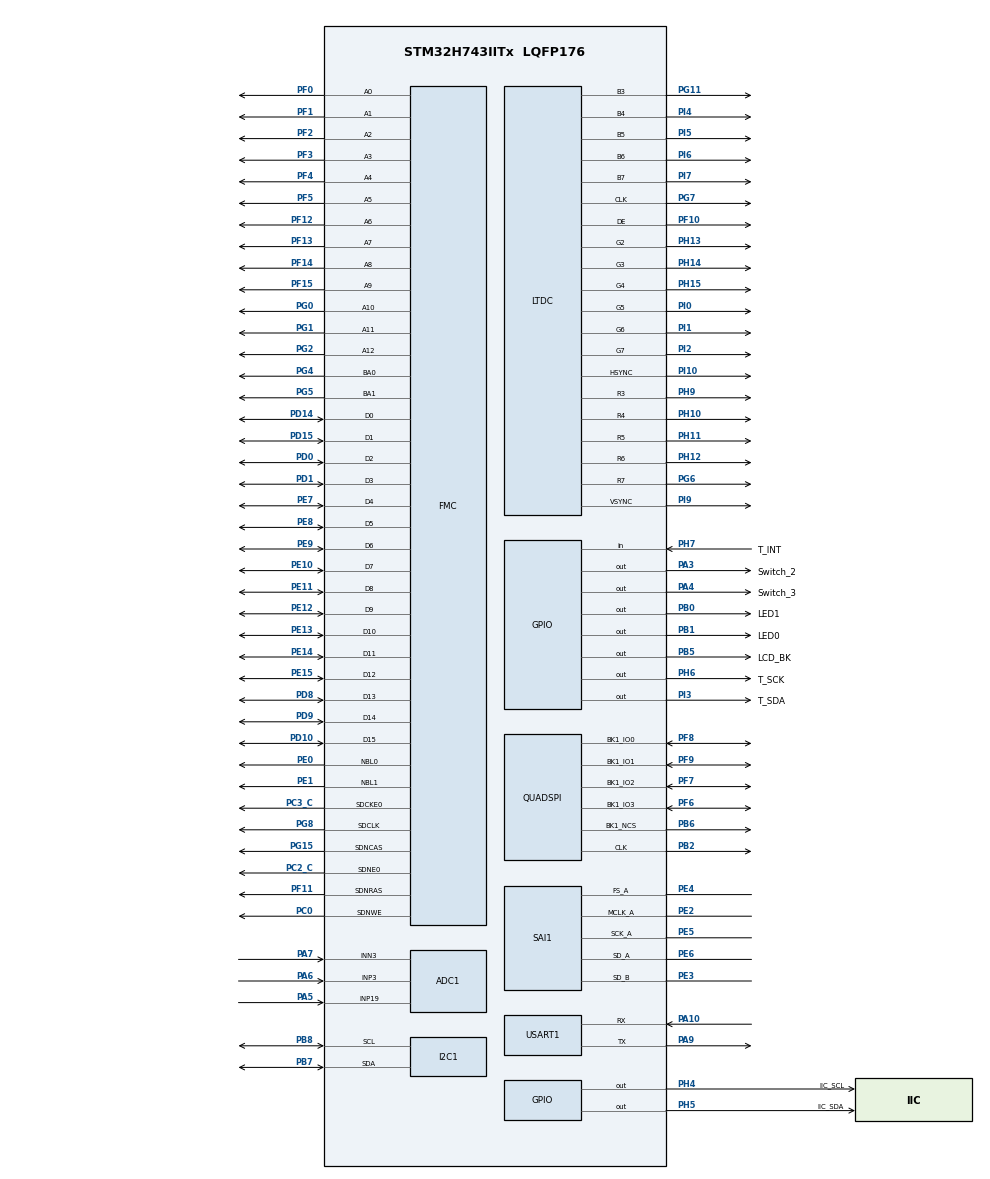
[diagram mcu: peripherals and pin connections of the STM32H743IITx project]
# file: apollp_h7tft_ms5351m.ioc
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ADC1.Channel-0\#ChannelRegularConversion=ADC_CHANNEL_19
ADC1.ClockPrescaler=ADC_CLOCK_ASYNC_DIV4
ADC1.ClockPrescalerADC3=ADC_CLOCK_ASYNC_DIV4
ADC1.ConversionDataManagement=ADC_CONVERSIONDATA_DMA_ONESHOT
ADC1.EOCSelection=ADC_EOC_SEQ_CONV
ADC1.EnableInjectedConversion=ENABLE
ADC1.ExternalTrigConv=ADC_SOFTWARE_START
ADC1.ExternalTrigInjecConv=ADC_EXTERNALTRIGINJEC_T3_TRGO
ADC1.InjNumberOfConversion=1
ADC1.InjectedChannel-1\#ChannelInjectedConversion=ADC_CHANNEL_3
ADC1.InjectedOffsetNumber-1\#ChannelInjectedConversion=ADC_OFFSET_NONE
ADC1.InjectedOffsetSaturation-1\#ChannelInjectedConversion=DISABLE
ADC1.InjectedOffsetSignedSaturation-1\#ChannelInjectedConversion=DISABLE
ADC1.InjectedRank-1\#ChannelInjectedConversion=1
ADC1.InjectedSamplingTime-1\#ChannelInjectedConversion=ADC_SAMPLETIME_64CYCLES_5
ADC1.InjectedSingleDiff-1\#ChannelInjectedConversion=ADC_DIFFERENTIAL_ENDED
ADC1.NbrOfConversionFlag=1
ADC1.OffsetNumber-0\#ChannelRegularConversion=ADC_OFFSET_NONE
ADC1.OffsetSignedSaturation-0\#ChannelRegularConversion=DISABLE
ADC1.Overrun=ADC_OVR_DATA_OVERWRITTEN
ADC1.Rank-0\#ChannelRegularConversion=1
ADC1.SamplingTime-0\#ChannelRegularConversion=ADC_SAMPLETIME_64CYCLES_5
ADC1.master=1
ADC3.Channel-0\#ChannelRegularConversion=ADC_CHANNEL_TEMPSENSOR
ADC3.ClockPrescaler=ADC_CLOCK_ASYNC_DIV4
ADC3.ClockPrescalerADC3=ADC_CLOCK_ASYNC_DIV4
ADC3.NbrOfConversionFlag=1
ADC3.OffsetNumber-0\#ChannelRegularConversion=ADC_OFFSET_NONE
ADC3.OffsetSignedSaturation-0\#ChannelRegularConversion=DISABLE
ADC3.Overrun=ADC_OVR_DATA_OVERWRITTEN
ADC3.Rank-0\#ChannelRegularConversion=1
ADC3.SamplingTime-0\#ChannelRegularConversion=ADC_SAMPLETIME_810CYCLES_5
CORTEX_M7.AccessPermission-Cortex_Memory_Protection_Unit_Region1_Settings=MPU_REGION_FULL_ACCESS
CORTEX_M7.AccessPermission-Cortex_Memory_Protection_Unit_Region2_Settings=MPU_REGION_FULL_ACCESS
CORTEX_M7.AccessPermission-Cortex_Memory_Protection_Unit_Region3_Settings=MPU_REGION_FULL_ACCESS
CORTEX_M7.AccessPermission-Cortex_Memory_Protection_Unit_Region4_Settings=MPU_REGION_FULL_ACCESS
CORTEX_M7.AccessPermission-Cortex_Memory_Protection_Unit_Region5_Settings=MPU_REGION_FULL_ACCESS
CORTEX_M7.AccessPermission-Cortex_Memory_Protection_Unit_Region6_Settings=MPU_REGION_FULL_ACCESS
CORTEX_M7.BaseAddress-Cortex_Memory_Protection_Unit_Region1_Settings=0x24000000
CORTEX_M7.BaseAddress-Cortex_Memory_Protection_Unit_Region2_Settings=0xC0000000
CORTEX_M7.BaseAddress-Cortex_Memory_Protection_Unit_Region3_Settings=0x20000000
CORTEX_M7.BaseAddress-Cortex_Memory_Protection_Unit_Region4_Settings=0x30000000
CORTEX_M7.BaseAddress-Cortex_Memory_Protection_Unit_Region5_Settings=0x38000000
CORTEX_M7.BaseAddress-Cortex_Memory_Protection_Unit_Region6_Settings=0x60000000
CORTEX_M7.CPU_DCache=Enabled
CORTEX_M7.CPU_ICache=Enabled
CORTEX_M7.Enable-Cortex_Memory_Protection_Unit_Region0_Settings=__NULL
CORTEX_M7.Enable-Cortex_Memory_Protection_Unit_Region1_Settings=MPU_REGION_ENABLE
CORTEX_M7.Enable-Cortex_Memory_Protection_Unit_Region2_Settings=MPU_REGION_ENABLE
CORTEX_M7.Enable-Cortex_Memory_Protection_Unit_Region3_Settings=MPU_REGION_ENABLE
CORTEX_M7.Enable-Cortex_Memory_Protection_Unit_Region4_Settings=MPU_REGION_ENABLE
CORTEX_M7.Enable-Cortex_Memory_Protection_Unit_Region5_Settings=MPU_REGION_ENABLE
CORTEX_M7.Enable-Cortex_Memory_Protection_Unit_Region6_Settings=MPU_REGION_ENABLE
CORTEX_M7.IsBufferable-Cortex_Memory_Protection_Unit_Region1_Settings=MPU_ACCESS_BUFFERABLE
CORTEX_M7.IsBufferable-Cortex_Memory_Protection_Unit_Region2_Settings=MPU_ACCESS_BUFFERABLE
CORTEX_M7.IsBufferable-Cortex_Memory_Protection_Unit_Region3_Settings=MPU_ACCESS_BUFFERABLE
CORTEX_M7.IsBufferable-Cortex_Memory_Protection_Unit_Region4_Settings=MPU_ACCESS_BUFFERABLE
CORTEX_M7.IsBufferable-Cortex_Memory_Protection_Unit_Region5_Settings=MPU_ACCESS_BUFFERABLE
CORTEX_M7.IsCacheable-Cortex_Memory_Protection_Unit_Region1_Settings=MPU_ACCESS_CACHEABLE
CORTEX_M7.IsCacheable-Cortex_Memory_Protection_Unit_Region2_Settings=MPU_ACCESS_CACHEABLE
CORTEX_M7.IsCacheable-Cortex_Memory_Protection_Unit_Region3_Settings=MPU_ACCESS_CACHEABLE
CORTEX_M7.IsCacheable-Cortex_Memory_Protection_Unit_Region4_Settings=MPU_ACCESS_CACHEABLE
CORTEX_M7.IsShareable-Cortex_Memory_Protection_Unit_Region1_Settings=MPU_ACCESS_NOT_SHAREABLE
CORTEX_M7.MPU_Control=MPU_PRIVILEGED_DEFAULT
CORTEX_M7.Size-Cortex_Memory_Protection_Unit_Region1_Settings=MPU_REGION_SIZE_512KB
CORTEX_M7.Size-Cortex_Memory_Protection_Unit_Region2_Settings=MPU_REGION_SIZE_32MB
CORTEX_M7.Size-Cortex_Memory_Protection_Unit_Region3_Settings=MPU_REGION_SIZE_128KB
CORTEX_M7.Size-Cortex_Memory_Protection_Unit_Region4_Settings=MPU_REGION_SIZE_512KB
CORTEX_M7.Size-Cortex_Memory_Protection_Unit_Region5_Settings=MPU_REGION_SIZE_64KB
CORTEX_M7.Size-Cortex_Memory_Protection_Unit_Region6_Settings=MPU_REGION_SIZE_64MB
CORTEX_M7.default_mode_Activation=0
DMA2D.ColorMode=DMA2D_OUTPUT_RGB565
Dma.ADC1.0.Direction=DMA_PERIPH_TO_MEMORY
Dma.ADC1.0.EventEnable=DISABLE
Dma.ADC1.0.FIFOMode=DMA_FIFOMODE_DISABLE
Dma.ADC1.0.Instance=DMA1_Stream0
Dma.ADC1.0.MemDataAlignment=DMA_MDATAALIGN_HALFWORD
Dma.ADC1.0.MemInc=DMA_MINC_ENABLE
Dma.ADC1.0.Mode=DMA_CIRCULAR
Dma.ADC1.0.PeriphDataAlignment=DMA_PDATAALIGN_HALFWORD
Dma.ADC1.0.PeriphInc=DMA_PINC_DISABLE
Dma.ADC1.0.Polarity=HAL_DMAMUX_REQ_GEN_RISING
Dma.ADC1.0.Priority=DMA_PRIORITY_LOW
Dma.ADC1.0.RequestNumber=1
Dma.ADC1.0.SignalID=NONE
Dma.ADC1.0.SyncEnable=DISABLE
Dma.ADC1.0.SyncPolarity=HAL_DMAMUX_SYNC_NO_EVENT
Dma.ADC1.0.SyncRequestNumber=1
Dma.ADC1.0.SyncSignalID=NONE
Dma.MEMTOMEM.1.Direction=DMA_MEMORY_TO_MEMORY
Dma.MEMTOMEM.1.EventEnable=DISABLE
Dma.MEMTOMEM.1.FIFOMode=DMA_FIFOMODE_ENABLE
Dma.MEMTOMEM.1.FIFOThreshold=DMA_FIFO_THRESHOLD_1QUARTERFULL
Dma.MEMTOMEM.1.Instance=DMA2_Stream0
Dma.MEMTOMEM.1.MemBurst=DMA_MBURST_SINGLE
Dma.MEMTOMEM.1.MemDataAlignment=DMA_MDATAALIGN_HALFWORD
Dma.MEMTOMEM.1.MemInc=DMA_MINC_ENABLE
Dma.MEMTOMEM.1.Mode=DMA_NORMAL
Dma.MEMTOMEM.1.PeriphBurst=DMA_PBURST_SINGLE
Dma.MEMTOMEM.1.PeriphDataAlignment=DMA_PDATAALIGN_HALFWORD
Dma.MEMTOMEM.1.PeriphInc=DMA_PINC_ENABLE
Dma.MEMTOMEM.1.Polarity=HAL_DMAMUX_REQ_GEN_RISING
Dma.MEMTOMEM.1.Priority=DMA_PRIORITY_HIGH
Dma.MEMTOMEM.1.RequestNumber=1
Dma.MEMTOMEM.1.SignalID=NONE
Dma.MEMTOMEM.1.SyncEnable=DISABLE
Dma.MEMTOMEM.1.SyncPolarity=HAL_DMAMUX_SYNC_NO_EVENT
Dma.MEMTOMEM.1.SyncRequestNumber=1
Dma.MEMTOMEM.1.SyncSignalID=NONE
Dma.Request0=ADC1
Dma.Request1=MEMTOMEM
Dma.Request2=SAI1_A
Dma.Request3=SAI1_B
Dma.SAI1_A.2.Direction=DMA_MEMORY_TO_PERIPH
Dma.SAI1_A.2.EventEnable=DISABLE
Dma.SAI1_A.2.FIFOMode=DMA_FIFOMODE_DISABLE
Dma.SAI1_A.2.Instance=DMA1_Stream5
Dma.SAI1_A.2.MemDataAlignment=DMA_MDATAALIGN_WORD
Dma.SAI1_A.2.MemInc=DMA_MINC_ENABLE
Dma.SAI1_A.2.Mode=DMA_CIRCULAR
Dma.SAI1_A.2.PeriphDataAlignment=DMA_PDATAALIGN_WORD
Dma.SAI1_A.2.PeriphInc=DMA_PINC_DISABLE
Dma.SAI1_A.2.Polarity=HAL_DMAMUX_REQ_GEN_RISING
Dma.SAI1_A.2.Priority=DMA_PRIORITY_LOW
Dma.SAI1_A.2.RequestNumber=1
Dma.SAI1_A.2.SignalID=NONE
Dma.SAI1_A.2.SyncEnable=DISABLE
Dma.SAI1_A.2.SyncPolarity=HAL_DMAMUX_SYNC_NO_EVENT
Dma.SAI1_A.2.SyncRequestNumber=1
Dma.SAI1_A.2.SyncSignalID=NONE
Dma.SAI1_B.3.Direction=DMA_PERIPH_TO_MEMORY
Dma.SAI1_B.3.EventEnable=DISABLE
Dma.SAI1_B.3.FIFOMode=DMA_FIFOMODE_DISABLE
Dma.SAI1_B.3.Instance=DMA1_Stream3
Dma.SAI1_B.3.MemDataAlignment=DMA_MDATAALIGN_WORD
Dma.SAI1_B.3.MemInc=DMA_MINC_ENABLE
Dma.SAI1_B.3.Mode=DMA_NORMAL
Dma.SAI1_B.3.PeriphDataAlignment=DMA_PDATAALIGN_WORD
Dma.SAI1_B.3.PeriphInc=DMA_PINC_DISABLE
Dma.SAI1_B.3.Polarity=HAL_DMAMUX_REQ_GEN_RISING
Dma.SAI1_B.3.Priority=DMA_PRIORITY_HIGH
Dma.SAI1_B.3.RequestNumber=1
Dma.SAI1_B.3.SignalID=NONE
Dma.SAI1_B.3.SyncEnable=DISABLE
Dma.SAI1_B.3.SyncPolarity=HAL_DMAMUX_SYNC_NO_EVENT
Dma.SAI1_B.3.SyncRequestNumber=1
Dma.SAI1_B.3.SyncSignalID=NONE
FMC.CASLatency1=FMC_SDRAM_CAS_LATENCY_3
FMC.ColumnBitsNumber1=FMC_SDRAM_COLUMN_BITS_NUM_9
FMC.ExitSelfRefreshDelay1=7
FMC.LoadToActiveDelay1=2
FMC.RCDDelay1=2
FMC.RPDelay1=2
FMC.RPDelay2=2
FMC.ReadBurst1=FMC_SDRAM_RBURST_ENABLE
FMC.ReadBurst2=FMC_SDRAM_RBURST_ENABLE
FMC.ReadPipeDelay1=FMC_SDRAM_RPIPE_DELAY_1
FMC.ReadPipeDelay2=FMC_SDRAM_RPIPE_DELAY_1
FMC.RowCycleDelay1=7
FMC.RowCycleDelay2=7
FMC.SDClockPeriod1=FMC_SDRAM_CLOCK_PERIOD_2
FMC.SDClockPeriod2=FMC_SDRAM_CLOCK_PERIOD_2
FMC.SelfRefreshTime1=4
FMC.WriteRecoveryTime1=3
I2C1.Timing=0x307075B1
LTDC.ActiveH=PIXELS_H
LTDC.ActiveW=PIXELS_W
LTDC.Alpha_L0=255
LTDC.Alpha_L1=255
LTDC.FBStartAdress_L0=0xC0000000
LTDC.FBStartAdress_L1=0xC0200000
LTDC.Green_L0=0
LTDC.HBP=140
LTDC.HFP=160
LTDC.HSync=20
LTDC.ImageHeight_L0=600
LTDC.ImageHeight_L1=600
LTDC.ImageWidth_L0=1024
LTDC.Layers=0
LTDC.PixelFormat_L0=LTDC_PIXEL_FORMAT_RGB565
LTDC.Red_L1=0
LTDC.VBP=20
LTDC.VFP=12
LTDC.VSync=3
LTDC.WindowX1_L0=PIXELS_W
LTDC.WindowX1_L1=PIXELS_W
LTDC.WindowY1_L0=PIXELS_H
LTDC.WindowY1_L1=PIXELS_H
Mcu.Family=STM32H7
Mcu.Name=STM32H743IITx
Mcu.Package=LQFP176
Mcu.UserConstants=PIXELS_DIR,1;PIXELS_H,600;PIXELS_W,1024;LTDC_BUFF_ADDR1,SDRAM_BANK_ADDR + SDRAM_LCD_SIZE;LTDC_BUFF_ADDR,SDRAM_BANK_ADDR
NVIC.ADC_IRQn=true\:0\:0\:false\:false\:true\:true\:true\:true
NVIC.DMA1_Stream0_IRQn=true\:2\:0\:true\:false\:true\:false\:true\:true
NVIC.DMA2D_IRQn=true\:0\:0\:false\:false\:true\:true\:true\:true
NVIC.PriorityGroup=NVIC_PRIORITYGROUP_4
NVIC.USART1_IRQn=true\:3\:0\:true\:false\:true\:true\:true\:true
PA10.Mode=Asynchronous
PA10.Signal=USART1_RX
PA13\ (JTMS/SWDIO).Mode=Serial_Wire
PA13\ (JTMS/SWDIO).Signal=DEBUG_JTMS-SWDIO
PA14\ (JTCK/SWCLK).Mode=Serial_Wire
PA14\ (JTCK/SWCLK).Signal=DEBUG_JTCK-SWCLK
PA3.GPIO_Label=Switch_2
PA3.GPIO_PuPd=GPIO_PULLUP
PA3.Signal=GPIO_Output
PA4.GPIO_Label=Switch_3
PA4.GPIO_PuPd=GPIO_PULLUP
PA4.Signal=GPIO_Output
PA5.Signal=ADCx_INP19
PA6.Signal=ADCx_INP3
PA7.Signal=ADCx_INN3
PA9.Mode=Asynchronous
PA9.Signal=USART1_TX
PB0.GPIO_Label=LED1
PB0.PinState=GPIO_PIN_SET
PB0.Signal=GPIO_Output
PB1.GPIO_Label=LED0
PB1.PinState=GPIO_PIN_SET
PB1.Signal=GPIO_Output
PB2.Mode=Single Bank 1
PB2.Signal=QUADSPI_CLK
PB5.GPIO_Label=LCD_BK
PB5.GPIO_PuPd=GPIO_PULLUP
PB5.Signal=GPIO_Output
PB6.GPIO_PuPd=GPIO_PULLUP
PB6.Mode=Single Bank 1
PB6.Signal=QUADSPI_BK1_NCS
PB7.Mode=I2C
PB7.Signal=I2C1_SDA
PB8.Mode=I2C
PB8.Signal=I2C1_SCL
PC0.Signal=FMC_SDNWE
PC14-OSC32_IN\ (OSC32_IN).Mode=LSE-External-Oscillator
PC14-OSC32_IN\ (OSC32_IN).Signal=RCC_OSC32_IN
PC15-OSC32_OUT\ (OSC32_OUT).Mode=LSE-External-Oscillator
PC15-OSC32_OUT\ (OSC32_OUT).Signal=RCC_OSC32_OUT
PC2_C.Mode=SdramChipSelect1_1
PC2_C.Signal=FMC_SDNE0
PC3_C.Mode=SdramChipSelect1_1
PC3_C.Signal=FMC_SDCKE0
PD0.Signal=FMC_D2_DA2
PD1.Signal=FMC_D3_DA3
PD10.Signal=FMC_D15_DA15
PD14.Signal=FMC_D0_DA0
PD15.Signal=FMC_D1_DA1
PD8.Signal=FMC_D13_DA13
PD9.Signal=FMC_D14_DA14
PE0.Signal=FMC_NBL0
PE1.Signal=FMC_NBL1
PE10.Signal=FMC_D7_DA7
PE11.Signal=FMC_D8_DA8
PE12.Signal=FMC_D9_DA9
PE13.Signal=FMC_D10_DA10
PE14.Signal=FMC_D11_DA11
PE15.Signal=FMC_D12_DA12
PE2.Mode=SAI_A_MasterWithClock
PE2.Signal=SAI1_MCLK_A
PE3.Mode=SAI_B_SyncSlave
PE3.Signal=SAI1_SD_B
PE4.Mode=SAI_A_MasterWithClock
PE4.Signal=SAI1_FS_A
PE5.Mode=SAI_A_MasterWithClock
PE5.Signal=SAI1_SCK_A
PE6.Mode=SAI_A_MasterWithClock
PE6.Signal=SAI1_SD_A
PE7.Signal=FMC_D4_DA4
PE8.Signal=FMC_D5_DA5
PE9.Signal=FMC_D6_DA6
PF0.Signal=FMC_A0
PF1.Signal=FMC_A1
PF10.GPIO_Speed=GPIO_SPEED_FREQ_VERY_HIGH
PF10.Mode=RGB565
PF10.Signal=LTDC_DE
PF11.Signal=FMC_SDNRAS
PF12.Signal=FMC_A6
PF13.Signal=FMC_A7
PF14.Signal=FMC_A8
PF15.Signal=FMC_A9
PF2.Signal=FMC_A2
PF3.Signal=FMC_A3
PF4.Signal=FMC_A4
PF5.Signal=FMC_A5
PF6.Mode=Single Bank 1
PF6.Signal=QUADSPI_BK1_IO3
PF7.Mode=Single Bank 1
PF7.Signal=QUADSPI_BK1_IO2
PF8.Mode=Single Bank 1
PF8.Signal=QUADSPI_BK1_IO0
PF9.Mode=Single Bank 1
PF9.Signal=QUADSPI_BK1_IO1
PG0.Signal=FMC_A10
PG1.Signal=FMC_A11
PG11.GPIO_Speed=GPIO_SPEED_FREQ_VERY_HIGH
PG11.Mode=RGB565
PG11.Signal=LTDC_B3
PG15.Signal=FMC_SDNCAS
PG2.Signal=FMC_A12
PG4.Signal=FMC_A14_BA0
PG5.Signal=FMC_A15_BA1
PG6.GPIO_Speed=GPIO_SPEED_FREQ_VERY_HIGH
PG6.Mode=RGB565
PG6.Signal=LTDC_R7
PG7.GPIO_Speed=GPIO_SPEED_FREQ_VERY_HIGH
PG7.Mode=RGB565
PG7.Signal=LTDC_CLK
PG8.Signal=FMC_SDCLK
PH0-OSC_IN\ (PH0).Mode=HSE-External-Oscillator
PH0-OSC_IN\ (PH0).Signal=RCC_OSC_IN
PH1-OSC_OUT\ (PH1).Mode=HSE-External-Oscillator
PH1-OSC_OUT\ (PH1).Signal=RCC_OSC_OUT
PH10.GPIO_Speed=GPIO_SPEED_FREQ_VERY_HIGH
PH10.Mode=RGB565
PH10.Signal=LTDC_R4
PH11.GPIO_Speed=GPIO_SPEED_FREQ_VERY_HIGH
PH11.Mode=RGB565
PH11.Signal=LTDC_R5
PH12.GPIO_Speed=GPIO_SPEED_FREQ_VERY_HIGH
PH12.Mode=RGB565
PH12.Signal=LTDC_R6
PH13.GPIO_Speed=GPIO_SPEED_FREQ_VERY_HIGH
PH13.Mode=RGB565
PH13.Signal=LTDC_G2
PH14.GPIO_Speed=GPIO_SPEED_FREQ_VERY_HIGH
PH14.Mode=RGB565
PH14.Signal=LTDC_G3
PH15.GPIO_Speed=GPIO_SPEED_FREQ_VERY_HIGH
PH15.Mode=RGB565
PH15.Signal=LTDC_G4
PH4.GPIO_Label=IIC_SCL
PH4.Signal=GPIO_Output
PH5.GPIO_Label=IIC_SDA
PH5.Signal=GPIO_Output
PH6.GPIO_Label=T_SCK
PH6.Signal=GPIO_Output
PH7.GPIO_Label=T_INT
PH7.Signal=GPIO_Input
PH9.GPIO_Speed=GPIO_SPEED_FREQ_VERY_HIGH
PH9.Mode=RGB565
PH9.Signal=LTDC_R3
PI0.GPIO_Speed=GPIO_SPEED_FREQ_VERY_HIGH
PI0.Mode=RGB565
PI0.Signal=LTDC_G5
PI1.GPIO_Speed=GPIO_SPEED_FREQ_VERY_HIGH
PI1.Mode=RGB565
PI1.Signal=LTDC_G6
PI10.GPIO_Speed=GPIO_SPEED_FREQ_VERY_HIGH
PI10.Mode=RGB565
PI10.Signal=LTDC_HSYNC
PI2.GPIO_Speed=GPIO_SPEED_FREQ_VERY_HIGH
PI2.Mode=RGB565
PI2.Signal=LTDC_G7
PI3.GPIO_Label=T_SDA
PI3.Signal=GPIO_Output
PI4.GPIO_Speed=GPIO_SPEED_FREQ_VERY_HIGH
PI4.Mode=RGB565
PI4.Signal=LTDC_B4
PI5.GPIO_Speed=GPIO_SPEED_FREQ_VERY_HIGH
PI5.Mode=RGB565
PI5.Signal=LTDC_B5
PI6.GPIO_Speed=GPIO_SPEED_FREQ_VERY_HIGH
PI6.Mode=RGB565
PI6.Signal=LTDC_B6
PI7.GPIO_Speed=GPIO_SPEED_FREQ_VERY_HIGH
PI7.Mode=RGB565
PI7.Signal=LTDC_B7
PI9.GPIO_Speed=GPIO_SPEED_FREQ_VERY_HIGH
PI9.Mode=RGB565
PI9.Signal=LTDC_VSYNC
ProjectManager.HeapSize=0x1000
ProjectManager.StackSize=0x2000
ProjectManager.TargetToolchain=Makefile
RCC.ADCFreq_Value=75000000
RCC.APB1Freq_Value=120000000
RCC.APB2Freq_Value=120000000
RCC.APB3Freq_Value=120000000
RCC.APB4Freq_Value=120000000
RCC.CortexFreq_Value=480000000
RCC.D1PPRE=RCC_APB3_DIV2
RCC.D2PPRE1=RCC_APB1_DIV2
RCC.D2PPRE2=RCC_APB2_DIV2
RCC.D3PPRE=RCC_APB4_DIV2
RCC.DIVM1=5
RCC.DIVM2=2
RCC.DIVM3=1
RCC.DIVN1=192
RCC.DIVN2=12
RCC.DIVN3=6
RCC.DIVQ1=7
RCC.DIVR3=3
RCC.HCLKFreq_Value=240000000
RCC.HPRE=RCC_HCLK_DIV2
RCC.PLL2FRACN=0
RCC.PLL3FRACN=0
RCC.PLLFRACN=0
RCC.PLLSourceVirtual=RCC_PLLSOURCE_HSE
RCC.RTCClockSelection=RCC_RTCCLKSOURCE_LSE
RCC.SAI1CLockSelection=RCC_SAI1CLKSOURCE_PLL2
RCC.SYSCLKFreq_VALUE=480000000
RCC.SYSCLKSource=RCC_SYSCLKSOURCE_PLLCLK
RCC.USBFreq_Value=137142857.14285713
SAI1.ActiveFrameLength-SAI_A_MasterWithClock=16
SAI1.ActiveFrameLength-SAI_B_SyncSlave=16
SAI1.ClockStrobing-SAI_A_MasterWithClock=SAI_CLOCKSTROBING_RISINGEDGE
SAI1.DataSize-SAI_A_MasterWithClock=SAI_DATASIZE_16
SAI1.DataSize-SAI_B_SyncSlave=SAI_DATASIZE_8
SAI1.ErrorAudioFreq-SAI_A_MasterWithClock=-23.7 %
SAI1.FIFOThreshold-SAI_A_MasterWithClock=SAI_FIFOTHRESHOLD_3QF
SAI1.FSDefinition-SAI_A_MasterWithClock=SAI_FS_STARTFRAME
SAI1.FSOffset-SAI_A_MasterWithClock=SAI_FS_BEFOREFIRSTBIT
SAI1.FSOffset-SAI_B_SyncSlave=SAI_FS_BEFOREFIRSTBIT
SAI1.FrameLength-SAI_A_MasterWithClock=32
SAI1.FrameLength-SAI_B_SyncSlave=32
SAI1.Instance-SAI_A_MasterWithClock=SAI$Index_Block_A
SAI1.Instance-SAI_B_SyncSlave=SAI$Index_Block_B
SAI1.MClockEnable-SAI_A_MasterWithClock=SAI_MASTERCLOCK_ENABLE
SAI1.OutputDrive-SAI_A_MasterWithClock=SAI_OUTPUTDRIVE_ENABLE
SAI1.RealAudioFreq-SAI_A_MasterWithClock=146.484 KHz
SAI1.SlotActive-SAI_A_MasterWithClock=0x00000003
SAI1.SlotNumber-SAI_A_MasterWithClock=2
SAI1.SlotSize-SAI_A_MasterWithClock=SAI_SLOTSIZE_16B
SAI1.SlotSize-SAI_B_SyncSlave=SAI_SLOTSIZE_16B
SAI1.VirtualMode-SAI_A_MasterWithClock=VM_MASTER
SAI1.VirtualMode-SAI_B_SyncSlave=VM_SLAVE
SAI1.VirtualSlotActive-SAI_A_MasterWithClock=SAI_SLOT_USERSETTING
SAI1.VirtualSlotActive0-SAI_A_MasterWithClock=true
SAI1.VirtualSlotActive1-SAI_A_MasterWithClock=true
SH.ADCx_INN3.0=ADC1_INN3,IN3-Differential
SH.ADCx_INP19.0=ADC1_INP19,IN19-Single-Ended
SH.ADCx_INP3.0=ADC1_INP3,IN3-Differential
SH.FMC_A0.0=FMC_A0,13b-sda1
SH.FMC_A1.0=FMC_A1,13b-sda1
SH.FMC_A10.0=FMC_A10,13b-sda1
SH.FMC_A11.0=FMC_A11,13b-sda1
SH.FMC_A12.0=FMC_A12,13b-sda1
SH.FMC_A14_BA0.0=FMC_BA0,FourSdramBanks1
SH.FMC_A15_BA1.0=FMC_BA1,FourSdramBanks1
SH.FMC_A2.0=FMC_A2,13b-sda1
SH.FMC_A3.0=FMC_A3,13b-sda1
SH.FMC_A4.0=FMC_A4,13b-sda1
SH.FMC_A5.0=FMC_A5,13b-sda1
SH.FMC_A6.0=FMC_A6,13b-sda1
SH.FMC_A7.0=FMC_A7,13b-sda1
SH.FMC_A8.0=FMC_A8,13b-sda1
SH.FMC_A9.0=FMC_A9,13b-sda1
SH.FMC_D0_DA0.0=FMC_D0,sd-16b-d1
SH.FMC_D10_DA10.0=FMC_D10,sd-16b-d1
SH.FMC_D11_DA11.0=FMC_D11,sd-16b-d1
SH.FMC_D12_DA12.0=FMC_D12,sd-16b-d1
SH.FMC_D13_DA13.0=FMC_D13,sd-16b-d1
SH.FMC_D14_DA14.0=FMC_D14,sd-16b-d1
SH.FMC_D15_DA15.0=FMC_D15,sd-16b-d1
SH.FMC_D1_DA1.0=FMC_D1,sd-16b-d1
SH.FMC_D2_DA2.0=FMC_D2,sd-16b-d1
SH.FMC_D3_DA3.0=FMC_D3,sd-16b-d1
SH.FMC_D4_DA4.0=FMC_D4,sd-16b-d1
SH.FMC_D5_DA5.0=FMC_D5,sd-16b-d1
SH.FMC_D6_DA6.0=FMC_D6,sd-16b-d1
SH.FMC_D7_DA7.0=FMC_D7,sd-16b-d1
SH.FMC_D8_DA8.0=FMC_D8,sd-16b-d1
SH.FMC_D9_DA9.0=FMC_D9,sd-16b-d1
SH.FMC_NBL0.0=FMC_NBL0,Sd2ByteEnable1
SH.FMC_NBL1.0=FMC_NBL1,Sd2ByteEnable1
SH.FMC_SDCLK.0=FMC_SDCLK,13b-sda1
SH.FMC_SDNCAS.0=FMC_SDNCAS,13b-sda1
SH.FMC_SDNRAS.0=FMC_SDNRAS,13b-sda1
SH.FMC_SDNWE.0=FMC_SDNWE,13b-sda1
TIM3.Period=5-1
TIM3.Prescaler=375-1
TIM3.TIM_MasterOutputTrigger=TIM_TRGO_UPDATE
USART1.VirtualMode-Asynchronous=VM_ASYNC
VP_ADC3_TempSens_Input.Mode=IN-TempSens
VP_CRC_VS_CRC.Mode=CRC_Activate
VP_DMA2D_VS_DMA2D.Mode=DMA2D_Activate
VP_MEMORYMAP_VS_MEMORYMAP.Mode=CurAppReg
VP_RTC_VS_RTC_Activate.Mode=RTC_Enabled
VP_TIM3_VS_ClockSourceINT.Mode=Internal
board=custom

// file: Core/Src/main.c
/* USER CODE BEGIN Header */
/**
  ******************************************************************************
  * @file           : main.c
  * @brief          : Main program body
  ******************************************************************************
  * @attention
  *
  * Copyright (c) 2026 STMicroelectronics.
  * All rights reserved.
  *
  * This software is licensed under terms that can be found in the LICENSE file
  * in the root directory of this software component.
  * If no LICENSE file comes with this software, it is provided AS-IS.
  *
  ******************************************************************************
  */
/* USER CODE END Header */
#include "main.h"
#include "adc.h"
#include "crc.h"
#include "dma.h"
#include "dma2d.h"
#include "i2c.h"
#include "ltdc.h"
#include "quadspi.h"
#include "rtc.h"
#include "sai.h"
#include "tim.h"
#include "usart.h"
#include "gpio.h"
#include "fmc.h"

/* USER CODE BEGIN Includes */
#include "app.h"
/* USER CODE END Includes */

void SystemClock_Config(void);
void PeriphCommonClock_Config(void);
static void MPU_Config(void);

int main(void)
{

  /* MPU Configuration--------------------------------------------------------*/
  MPU_Config();

  /* Enable the CPU Cache */

  /* Enable I-Cache---------------------------------------------------------*/
  SCB_EnableICache();

  /* Enable D-Cache---------------------------------------------------------*/
  SCB_EnableDCache();

  /* MCU Configuration--------------------------------------------------------*/

  /* Reset of all peripherals, Initializes the Flash interface and the Systick. */
  HAL_Init();

  /* Configure the system clock */
  SystemClock_Config();

  /* Configure the peripherals common clocks */
  PeriphCommonClock_Config();

  /* Initialize all configured peripherals */
  MX_GPIO_Init();
  MX_DMA_Init();
  MX_FMC_Init();
  MX_LTDC_Init();
  MX_ADC1_Init();
  MX_TIM3_Init();
  MX_USART1_UART_Init();
  MX_DMA2D_Init();
  MX_CRC_Init();
  MX_QUADSPI_Init();
  MX_ADC3_Init();
  MX_RTC_Init();
  MX_SAI1_Init();
  MX_I2C1_Init();
  /* USER CODE BEGIN 2 */

  /* --- SDRAM JEDEC power-up sequence (CubeMX doesn't generate it) ------- */
  {
    FMC_SDRAM_CommandTypeDef cmd = {0};

    cmd.CommandTarget = FMC_SDRAM_CMD_TARGET_BANK1;
    cmd.AutoRefreshNumber = 1;
    cmd.ModeRegisterDefinition = 0;

    cmd.CommandMode = FMC_SDRAM_CMD_CLK_ENABLE;
    HAL_SDRAM_SendCommand(&hsdram1, &cmd, 0xFFFFU);
    HAL_Delay(1);

    cmd.CommandMode = FMC_SDRAM_CMD_PALL;
    HAL_SDRAM_SendCommand(&hsdram1, &cmd, 0xFFFFU);

    cmd.CommandMode = FMC_SDRAM_CMD_AUTOREFRESH_MODE;
    cmd.AutoRefreshNumber = 8;
    HAL_SDRAM_SendCommand(&hsdram1, &cmd, 0xFFFFU);

    cmd.CommandMode = FMC_SDRAM_CMD_LOAD_MODE;
    cmd.AutoRefreshNumber = 1;
    cmd.ModeRegisterDefinition = 0x0230U;   /* burst 1 / single write / CAS 3 */
    HAL_SDRAM_SendCommand(&hsdram1, &cmd, 0xFFFFU);

    HAL_SDRAM_ProgramRefreshRate(&hsdram1, 1667U);
  }

  /* --- Backlight on (LCD_BK = PB5) -------------------------------------- */
  HAL_GPIO_WritePin(GPIOB, GPIO_PIN_5, GPIO_PIN_SET);
  HAL_Delay(20);

  /* --- Four colour bars: red / green / blue / white --------------------- */
  {
    uint16_t *fb = (uint16_t *)0xC0000000UL;
    uint32_t x;
    uint32_t y;

    for (y = 0U; y < 600U; y++)
    {
      for (x = 0U; x < 1024U; x++)
      {
        uint16_t c;

        if (x < 256U)       { c = 0xF800U; }   /* red   */
        else if (x < 512U)  { c = 0x07E0U; }   /* green */
        else if (x < 768U)  { c = 0x001FU; }   /* blue  */
        else                { c = 0xFFFFU; }   /* white */

        fb[(y * 1024U) + x] = c;
      }
    }

    /* 0xC0000000 is cacheable (MPU region 2): push it out so the LTDC,
       which bypasses the D-Cache, actually sees the pixels.               */
    SCB_CleanDCache_by_Addr((uint32_t *)0xC0000000UL, 1024 * 600 * 2);
  }

  /* --- Signal generator UI (LVGL) --------------------------------------- */
  app_init();

  /* USER CODE END 2 */

  /* Infinite loop */
  while (1)
  {

    /* USER CODE BEGIN 3 */
    app_process();
  }
  /* USER CODE END 3 */
}

void SystemClock_Config(void)
{
  RCC_OscInitTypeDef RCC_OscInitStruct = {0};
  RCC_ClkInitTypeDef RCC_ClkInitStruct = {0};

  /** Supply configuration update enable
  */
  HAL_PWREx_ConfigSupply(PWR_LDO_SUPPLY);

  /** Configure the main internal regulator output voltage
  */
  __HAL_PWR_VOLTAGESCALING_CONFIG(PWR_REGULATOR_VOLTAGE_SCALE0);

  while(!__HAL_PWR_GET_FLAG(PWR_FLAG_VOSRDY)) {}

  /** Configure LSE Drive Capability
  */
  HAL_PWR_EnableBkUpAccess();
  __HAL_RCC_LSEDRIVE_CONFIG(RCC_LSEDRIVE_LOW);

  /** Initializes the RCC Oscillators according to the specified parameters
  * in the RCC_OscInitTypeDef structure.
  */
  RCC_OscInitStruct.OscillatorType = RCC_OSCILLATORTYPE_HSE|RCC_OSCILLATORTYPE_LSE;
  RCC_OscInitStruct.HSEState = RCC_HSE_ON;
  RCC_OscInitStruct.LSEState = RCC_LSE_ON;
  RCC_OscInitStruct.PLL.PLLState = RCC_PLL_ON;
  RCC_OscInitStruct.PLL.PLLSource = RCC_PLLSOURCE_HSE;
  RCC_OscInitStruct.PLL.PLLM = 5;
  RCC_OscInitStruct.PLL.PLLN = 192;
  RCC_OscInitStruct.PLL.PLLP = 2;
  RCC_OscInitStruct.PLL.PLLQ = 7;
  RCC_OscInitStruct.PLL.PLLR = 2;
  RCC_OscInitStruct.PLL.PLLRGE = RCC_PLL1VCIRANGE_2;
  RCC_OscInitStruct.PLL.PLLVCOSEL = RCC_PLL1VCOWIDE;
  RCC_OscInitStruct.PLL.PLLFRACN = 0;
  if (HAL_RCC_OscConfig(&RCC_OscInitStruct) != HAL_OK)
  {
    Error_Handler();
  }

  /** Initializes the CPU, AHB and APB buses clocks
  */
  RCC_ClkInitStruct.ClockType = RCC_CLOCKTYPE_HCLK|RCC_CLOCKTYPE_SYSCLK
                              |RCC_CLOCKTYPE_PCLK1|RCC_CLOCKTYPE_PCLK2
                              |RCC_CLOCKTYPE_D3PCLK1|RCC_CLOCKTYPE_D1PCLK1;
  RCC_ClkInitStruct.SYSCLKSource = RCC_SYSCLKSOURCE_PLLCLK;
  RCC_ClkInitStruct.SYSCLKDivider = RCC_SYSCLK_DIV1;
  RCC_ClkInitStruct.AHBCLKDivider = RCC_HCLK_DIV2;
  RCC_ClkInitStruct.APB3CLKDivider = RCC_APB3_DIV2;
  RCC_ClkInitStruct.APB1CLKDivider = RCC_APB1_DIV2;
  RCC_ClkInitStruct.APB2CLKDivider = RCC_APB2_DIV2;
  RCC_ClkInitStruct.APB4CLKDivider = RCC_APB4_DIV2;

  if (HAL_RCC_ClockConfig(&RCC_ClkInitStruct, FLASH_LATENCY_4) != HAL_OK)
  {
    Error_Handler();
  }
}

void PeriphCommonClock_Config(void)
{
  RCC_PeriphCLKInitTypeDef PeriphClkInitStruct = {0};

  /** Initializes the peripherals clock
  */
  PeriphClkInitStruct.PeriphClockSelection = RCC_PERIPHCLK_ADC|RCC_PERIPHCLK_SAI1;
  PeriphClkInitStruct.PLL2.PLL2M = 2;
  PeriphClkInitStruct.PLL2.PLL2N = 12;
  PeriphClkInitStruct.PLL2.PLL2P = 2;
  PeriphClkInitStruct.PLL2.PLL2Q = 2;
  PeriphClkInitStruct.PLL2.PLL2R = 2;
  PeriphClkInitStruct.PLL2.PLL2RGE = RCC_PLL2VCIRANGE_3;
  PeriphClkInitStruct.PLL2.PLL2VCOSEL = RCC_PLL2VCOMEDIUM;
  PeriphClkInitStruct.PLL2.PLL2FRACN = 0;
  PeriphClkInitStruct.Sai1ClockSelection = RCC_SAI1CLKSOURCE_PLL2;
  PeriphClkInitStruct.AdcClockSelection = RCC_ADCCLKSOURCE_PLL2;
  if (HAL_RCCEx_PeriphCLKConfig(&PeriphClkInitStruct) != HAL_OK)
  {
    Error_Handler();
  }
}

 /* MPU Configuration */

void MPU_Config(void)
{
  MPU_Region_InitTypeDef MPU_InitStruct = {0};

  /* Disables the MPU */
  HAL_MPU_Disable();

  /** Initializes and configures the Region and the memory to be protected
  */
  MPU_InitStruct.Enable = MPU_REGION_ENABLE;
  MPU_InitStruct.Number = MPU_REGION_NUMBER1;
  MPU_InitStruct.BaseAddress = 0x24000000;
  MPU_InitStruct.Size = MPU_REGION_SIZE_512KB;
  MPU_InitStruct.SubRegionDisable = 0x0;
  MPU_InitStruct.TypeExtField = MPU_TEX_LEVEL0;
  MPU_InitStruct.AccessPermission = MPU_REGION_FULL_ACCESS;
  MPU_InitStruct.DisableExec = MPU_INSTRUCTION_ACCESS_ENABLE;
  MPU_InitStruct.IsShareable = MPU_ACCESS_NOT_SHAREABLE;
  MPU_InitStruct.IsCacheable = MPU_ACCESS_CACHEABLE;
  MPU_InitStruct.IsBufferable = MPU_ACCESS_BUFFERABLE;

  HAL_MPU_ConfigRegion(&MPU_InitStruct);

  /** Initializes and configures the Region and the memory to be protected
  */
  MPU_InitStruct.Number = MPU_REGION_NUMBER2;
  MPU_InitStruct.BaseAddress = 0xC0000000;
  MPU_InitStruct.Size = MPU_REGION_SIZE_32MB;

  HAL_MPU_ConfigRegion(&MPU_InitStruct);

  /** Initializes and configures the Region and the memory to be protected
  */
  MPU_InitStruct.Number = MPU_REGION_NUMBER3;
  MPU_InitStruct.BaseAddress = 0x20000000;
  MPU_InitStruct.Size = MPU_REGION_SIZE_128KB;

  HAL_MPU_ConfigRegion(&MPU_InitStruct);

  /** Initializes and configures the Region and the memory to be protected
  */
  MPU_InitStruct.Number = MPU_REGION_NUMBER4;
  MPU_InitStruct.BaseAddress = 0x30000000;
  MPU_InitStruct.Size = MPU_REGION_SIZE_512KB;

  HAL_MPU_ConfigRegion(&MPU_InitStruct);

  /** Initializes and configures the Region and the memory to be protected
  */
  MPU_InitStruct.Number = MPU_REGION_NUMBER5;
  MPU_InitStruct.BaseAddress = 0x38000000;
  MPU_InitStruct.Size = MPU_REGION_SIZE_64KB;
  MPU_InitStruct.IsCacheable = MPU_ACCESS_NOT_CACHEABLE;

  HAL_MPU_ConfigRegion(&MPU_InitStruct);

  /** Initializes and configures the Region and the memory to be protected
  */
  MPU_InitStruct.Number = MPU_REGION_NUMBER6;
  MPU_InitStruct.BaseAddress = 0x60000000;
  MPU_InitStruct.Size = MPU_REGION_SIZE_64MB;
  MPU_InitStruct.IsBufferable = MPU_ACCESS_NOT_BUFFERABLE;

  HAL_MPU_ConfigRegion(&MPU_InitStruct);
  /* Enables the MPU */
  HAL_MPU_Enable(MPU_PRIVILEGED_DEFAULT);

}

void Error_Handler(void)
{
  __disable_irq();
  while (1)
  {
  }
}
